# RX64M_SRC_Pilot register map
File version: 1.0
RX64M_SRC_Pilot peripheral registers generated from iodefine.h (pilot).
Registers are 16-bit, read-write, reset 0x0 unless marked. A register's access mark holds for its fields unless they carry their own. Offsets are from the block's base; lines under a group give offsets from that group; [hi:lo] are bit positions; {n}, {i} and the like mark numbered series; 'fields as' and 'values as' point back to an identical list; <NAME> marks a mode.

## Memory map
0x00098000 SRC size 0x6000

## SRC
Base 0x00098000
{0x0+4i} SRCFCTR{i} (i=0..5551) 32-bit (reset mask 0xFFC00000)
0x5FF0 SRCID 32-bit
0x5FF4 SRCOD 32-bit ro
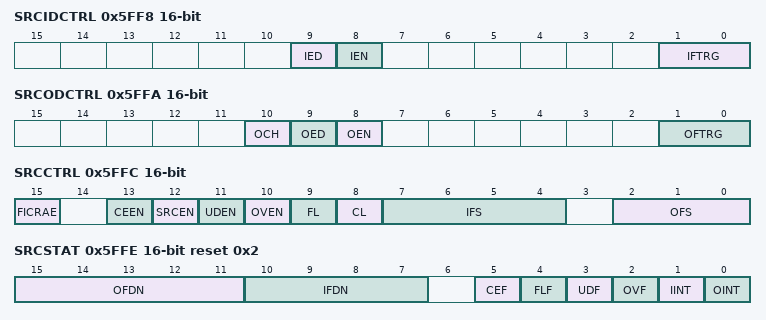
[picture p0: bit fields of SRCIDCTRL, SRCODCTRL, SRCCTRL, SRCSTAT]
0x5FF8 SRCIDCTRL
  [9] IED, [8] IEN, [1:0] IFTRG
0x5FFA SRCODCTRL
  [10] OCH, [9] OED, [8] OEN, [1:0] OFTRG
0x5FFC SRCCTRL
  [15] FICRAE, [13] CEEN, [12] SRCEN, [11] UDEN, [10] OVEN, [9] FL, [8] CL, [7:4] IFS, [2:0] OFS
0x5FFE SRCSTAT reset 0x2
  [15:11] OFDN, [10:7] IFDN, [5] CEF, [4] FLF, [3] UDF, [2] OVF, [1] IINT, [0] OINT
